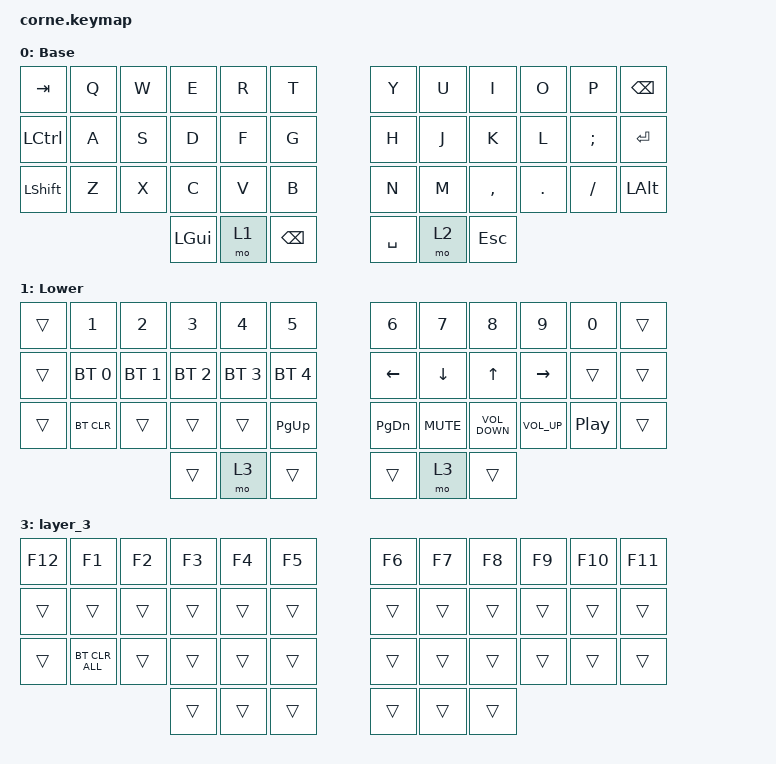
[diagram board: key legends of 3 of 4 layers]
/*
 * Copyright (c) 2020 The ZMK Contributors
 *
 * SPDX-License-Identifier: MIT
 */

#include <behaviors.dtsi>
#include <dt-bindings/zmk/bt.h>
#include <dt-bindings/zmk/keys.h>

/ {
    keymap {
        compatible = "zmk,keymap";

        default_layer {
            // -----------------------------------------------------------------------------------------
            // |  TAB |  Q  |  W  |  E  |  R  |  T   |   |  Y  |  U   |  I  |  O  |  P  | BSPC |
            // | CTRL |  A  |  S  |  D  |  F  |  G   |   |  H  |  J   |  K  |  L  |  ;  | ENT  |
            // | SHFT |  Z  |  X  |  C  |  V  |  B   |   |  N  |  M   |  ,  |  .  |  /  | ALT  |
            //                    | GUI | LWR | BSPC |   | SPC | RSE  | ESC |

            label = "Base";
            bindings = <
&kp TAB    &kp Q  &kp W  &kp E     &kp R  &kp T            &kp Y      &kp U  &kp I      &kp O    &kp P     &kp BSPC
&kp LCTRL  &kp A  &kp S  &kp D     &kp F  &kp G            &kp H      &kp J  &kp K      &kp L    &kp SEMI  &kp ENTER
&kp LSHFT  &kp Z  &kp X  &kp C     &kp V  &kp B            &kp N      &kp M  &kp COMMA  &kp DOT  &kp FSLH  &kp LEFT_ALT
                         &kp LGUI  &mo 1  &kp BACKSPACE    &kp SPACE  &mo 2  &kp ESC
            >;
        };

        lower_layer {
            // -----------------------------------------------------------------------------------------
            // |   |  1  |  2  |  3  |  4  |  5  |   |  6  |  7  |  8  |  9  |  0  |   |
            // |   | BT1 | BT2 | BT3 | BT4 | BT5 |   | LFT | DWN | UP  | RGT |     |   |
            // |   | BTX |     |     |     |     |   | MUT | VDN | VUP | PP  |     |   |
            //                 | ... | ... | ... |   | ... | ... | ... |

            label = "Lower";
            bindings = <
&trans  &kp N1        &kp N2        &kp N3        &kp N4        &kp N5          &kp N6         &kp N7      &kp N8             &kp N9           &kp N0            &trans
&trans  &bt BT_SEL 0  &bt BT_SEL 1  &bt BT_SEL 2  &bt BT_SEL 3  &bt BT_SEL 4    &kp LEFT       &kp DOWN    &kp UP             &kp RIGHT        &trans            &trans
&trans  &bt BT_CLR    &trans        &trans        &trans        &kp PAGE_UP     &kp PAGE_DOWN  &kp K_MUTE  &kp C_VOLUME_DOWN  &kp C_VOLUME_UP  &kp C_PLAY_PAUSE  &trans
                                    &trans        &mo 3         &trans          &trans         &mo 3       &trans
            >;
        };

        raise_layer {
            // -----------------------------------------------------------------------------------------
            // | ` ~ |  !  |  @  |  #  |  $  |  %  |   |  ^  |  &  |  *  |  (  |  )  | DEL |
            // |     |     |     | UP  |     |     |   | - _ | = + | ' " | [ { | ] } | \ | |
            // |     |     | LFT | DWN | RGT |     |   |     |     |     |     |     |     |
            //                   | ... | ... | DEL |   | ... | ... | ... |

            label = "Raise";
            bindings = <
&kp GRAVE  &kp EXCL  &kp AT    &kp HASH  &kp DLLR   &kp PRCNT     &kp CARET  &kp AMPS   &kp KP_MULTIPLY   &kp LPAR  &kp RPAR         &kp BSPC
&trans     &trans    &trans    &kp UP    &trans     &trans        &kp MINUS  &kp EQUAL  &kp SINGLE_QUOTE  &kp LBKT  &kp RBKT         &kp BSLH
&trans     &trans    &kp LEFT  &kp DOWN  &kp RIGHT  &trans        &trans     &trans     &trans            &trans    &kp PRINTSCREEN  &kp PRINTSCREEN
                               &trans    &mo 3      &kp DELETE    &trans     &mo 3
            >;
        };

        layer_3 {
            bindings = <
&kp F12  &kp F1          &kp F2  &kp F3  &kp F4  &kp F5    &kp F6  &kp F7  &kp F8  &kp F9  &kp F10  &kp F11
&trans   &trans          &trans  &trans  &trans  &trans    &trans  &trans  &trans  &trans  &trans   &trans
&trans   &bt BT_CLR_ALL  &trans  &trans  &trans  &trans    &trans  &trans  &trans  &trans  &trans   &trans
                                 &trans  &trans  &trans    &trans  &trans  &trans
            >;
        };
    };
};
